# max32572 register map
Vendor: Maxim-Integrated; Series: ARMCM4; File version: 1.0
CPU: CM4 r2p1, little endian, MPU, FPU, 3 interrupt priority bits
Registers are 32-bit, read-write, reset 0x0 unless marked. A register's access mark holds for its fields unless they carry their own. Offsets are from the block's base; [hi:lo] are bit positions.

## SIR — System Initialization Registers.
Base 0x40000400
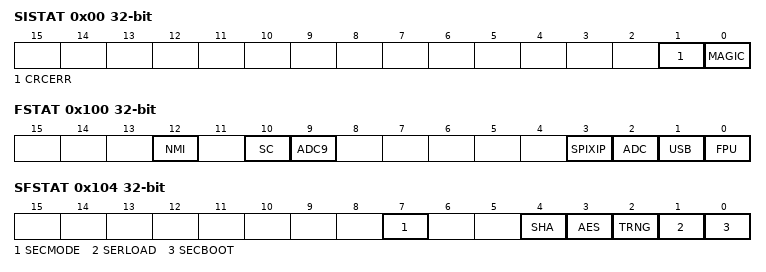
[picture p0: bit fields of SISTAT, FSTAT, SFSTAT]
0x00 SISTAT ro — System Initialization Status Register.
  [1] CRCERR — CRC Error Status. This bit is set by the system initialization block following power-up.
    on read: 0=noError (No CRC errors occurred during the read of the OTP memory block.); 1=error (A CRC error occurred while reading the OTP. The address of the failure location in the OTP memory is stored in the ERRADDR register.)
  [0] MAGIC — Magic Word Validation. This bit is set by the system initialization block following power-up.
    on read: 0=magicNotSet (Magic word was not set (OTP has not been initialized properly).); 1=magicSet (Magic word was set (OTP contains valid settings).)
0x04 SIADDR ro — Read-only field set by the SIB block if a CRC error occurs during the read of the OTP memory. Contains the failing address in OTP memory (when CRCERR equals 1).
  [31:0] ERRADDR
0x100 FSTAT ro — funcstat register.
  [all] fields
    0=no; 1=yes
  [12] NMI — NMI function.
  [10] SC — SC function.
  [9] ADC9 — ADC9 function.
  [3] SPIXIP — SPIXIPffunction.
  [2] ADC — 10-bit Sigma Delta ADC.
  [1] USB — USB Device.
  [0] FPU — FPU Function.
0x104 SFSTAT ro — Security Function
  [all] fields
    0=no; 1=yes
  [7] SECMODE — Security Mode Disable.
  [4] SHA — SHA function.
  [3] AES — AES function.
  [2] TRNG — TRNG function.
  [1] SERLOAD — Serial Load Disable function.
  [0] SECBOOT — Secure Boot Disable.

## SPIXFC_FIFO — SPI XiP Master Controller FIFO.
Base 0x400BC000
0x00 TX_8 8-bit — SPI TX FIFO 8-Bit Write
0x00 TX_16 16-bit (alternate view of TX_8) — SPI TX FIFO 16-Bit Write
0x00 TX_32 (alternate view of TX_8) — SPI TX FIFO 32-Bit Write
0x04 RX_8 8-bit — SPI RX FIFO 8-Bit Access
0x04 RX_16 16-bit (alternate view of RX_8) — SPI RX FIFO 16-Bit Access
0x04 RX_32 (alternate view of RX_8) — SPI RX FIFO 32-Bit Access

## TMR0 — 32-bit reloadable timer that can be used for timing and event counting.
Base 0x40010000
Same registers: TMR1 0x40011000, TMR2 0x40012000, TMR3 0x40013000, TMR4 0x40014000, TMR5 0x40015000
0x00 CNT reset 0x1 — Count. This register stores the current timer count.
  [31:0] COUNT
0x04 CMP reset 0xFFFF — Compare. This register stores the compare value, which is used to set the maximum count value to initiate a reload of the timer to 0x0001.
  [31:0] COMPARE
0x08 PWM — PWM. This register stores the value that is compared to the current timer count.
0x0C INTFL write-1-clears — Clear Interrupt. Writing a value (0 or 1) to a bit in this register clears the associated interrupt.
  [0] IRQ — Clear Interrupt.
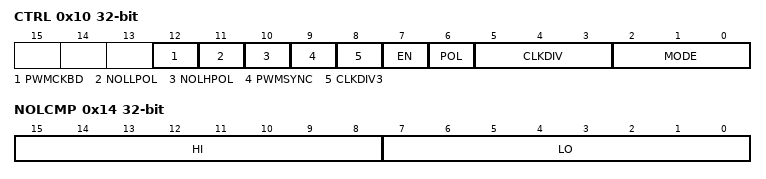
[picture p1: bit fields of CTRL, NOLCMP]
0x10 CTRL — Timer Control Register.
  [12] PWMCKBD — Timer PWM output 0A Mode Disable.
    1=dis (Disable.); 0=en (Enable.)
  [11] NOLLPOL — Timer PWM output 0A' polarity bit.
    0=dis (Disable.); 1=en (Enable.)
  [10] NOLHPOL — Timer PWM output 0A polarity bit.
    0=dis (Disable.); 1=en (Enable.)
  [9] PWMSYNC — Timer PWM Synchronization Mode Enable.
    0=dis (Disable.); 1=en (Enable.)
  [8] CLKDIV3 — MSB of prescaler value.
  [7] EN — Timer Enable.
    0=dis (Disable.); 1=en (Enable.)
  [6] POL — Timer input/output polarity bit.
    0=Active High; 1=Active Low
  [5:3] CLKDIV — Prescaler. Set the Timer's prescaler value. The prescaler divides the PCLK input to the timer and sets the Timer's Count Clock, F_CNT_CLK = PCLK (HZ) /prescaler. The Timer's prescaler setting is a 4-bit value with pres3:pres[2:0].
    0=div1 (Divide by 1.); 1=div2 (Divide by 2.); 2=div4 (Divide by 4.); 3=div8 (Divide by 8.); 4=div16 (Divide by 16.); 5=div32 (Divide by 32.); 6=div64 (Divide by 64.); 7=div128 (Divide by 128.)
  [2:0] MODE — Timer Mode.
    0=One Shot Mode; 1=Continuous Mode; 2=Counter Mode; 3=pwm (PWM Mode.); 4=Capture Mode; 5=Compare Mode; 6=Gated Mode; 7=Capture/Compare Mode
0x14 NOLCMP — Timer Non-Overlapping Compare Register.
  [15:8] HI — Non-overlapping High Compare. The 8-bit timer count value of non-overlapping time between falling edge of PWM output 0A' and next rising edge of PWM output 0A.
  [7:0] LO — Non-overlapping Low Compare. The 8-bit timer count value of non-overlapping time between falling edge of PWM output 0A and next rising edge of PWM output 0A'.
